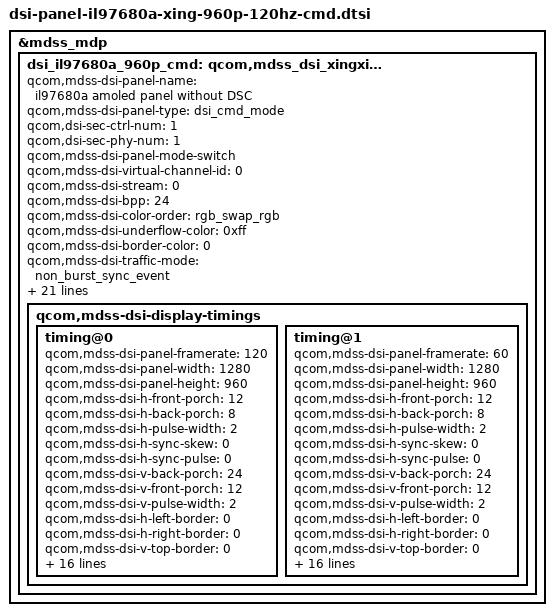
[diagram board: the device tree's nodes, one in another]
&mdss_mdp {
	dsi_il97680a_960p_cmd: qcom,mdss_dsi_xingxing_4_5_1280_960_cmd {
		qcom,mdss-dsi-panel-name =
		  "il97680a amoled panel without DSC";
		qcom,mdss-dsi-panel-type = "dsi_cmd_mode";
		qcom,dsi-sec-ctrl-num = <1>;
		qcom,dsi-sec-phy-num = <1>;


		qcom,mdss-dsi-panel-mode-switch;

		qcom,mdss-dsi-virtual-channel-id = <0>;
		qcom,mdss-dsi-stream = <0>;
		qcom,mdss-dsi-bpp = <24>;
		qcom,mdss-dsi-color-order = "rgb_swap_rgb";
		qcom,mdss-dsi-underflow-color = <0xff>;
		qcom,mdss-dsi-border-color = <0>;

		qcom,mdss-dsi-traffic-mode = "non_burst_sync_event";
		qcom,mdss-dsi-lane-map = "lane_map_0123";
		qcom,mdss-dsi-bllp-eof-power-mode;
		qcom,mdss-dsi-bllp-power-mode;
		qcom,mdss-dsi-lane-0-state;
		qcom,mdss-dsi-lane-1-state;
		qcom,mdss-dsi-lane-2-state;
		qcom,mdss-dsi-lane-3-state;
		qcom,mdss-dsi-dma-trigger = "trigger_sw";
		qcom,mdss-dsi-mdp-trigger = "none";
		qcom,mdss-dsi-reset-sequence = <1 20>, <0 20>, <1 20>;
		qcom,mdss-dsi-te-pin-select = <1>;
		qcom,mdss-dsi-wr-mem-start = <0x2c>;
		qcom,mdss-dsi-wr-mem-continue = <0x3c>;
		qcom,mdss-dsi-te-dcs-command = <1>;
		qcom,mdss-dsi-te-check-enable;
		// qcom,mdss-pan-physical-width-dimension = <68>;
		qcom,mdss-dsi-te-using-te-pin;
	//	qcom,mdss-dsi-te-using-wd;
		qcom,mdss-dsi-panel-hdr-enabled;
		qcom,mdss-dsi-panel-hdr-color-primaries = <14500 15500 32000
			17000 15500 30000 8000 3000>;
		qcom,mdss-dsi-panel-peak-brightness = <4200000>;
		qcom,mdss-dsi-panel-blackness-level = <3230>;

		qcom,mdss-dsi-display-timings {
			timing@0 {
				qcom,mdss-dsi-panel-framerate = <120>;
				qcom,mdss-dsi-panel-width = <1280>;
				qcom,mdss-dsi-panel-height = <960>;
				qcom,mdss-dsi-h-front-porch = <12>;
				qcom,mdss-dsi-h-back-porch = <8>;
				qcom,mdss-dsi-h-pulse-width = <2>;
				qcom,mdss-dsi-h-sync-skew = <0>;
				qcom,mdss-dsi-h-sync-pulse = <0>;
				qcom,mdss-dsi-v-back-porch = <24>;
				qcom,mdss-dsi-v-front-porch = <12>;
				qcom,mdss-dsi-v-pulse-width = <2>;
				qcom,mdss-dsi-h-left-border = <0>;
				qcom,mdss-dsi-h-right-border = <0>;
				qcom,mdss-dsi-v-top-border = <0>;
				qcom,mdss-dsi-v-bottom-border = <0>;
				qcom,mdss-dsi-panel-jitter = <0x3 0x1>;

				qcom,mdss-dsi-timing-switch-command = [
					39 01 00 00 00 00 04 FF 5A A5 00
					39 01 00 00 00 00 02 60 00
				];


				qcom,mdss-dsi-on-command = [
					39 01 00 00 00 00 04 FF 5A A5 08
					39 01 00 00 00 00 02 C8 62
					39 01 00 00 00 00 04 FF 5A A5 21
					39 01 00 00 00 00 02 A4 38
					39 01 00 00 00 00 04 FF 5A A5 23
					39 01 00 00 00 00 02 85 15
					39 01 00 00 00 00 04 FF 5A A5 00
					39 01 00 00 00 00 02 60 00
					39 01 00 00 00 00 02 6D 00
					05 01 00 00 00 00 01 35
					39 01 00 00 00 00 02 53 20
					39 01 00 00 00 00 05 51 0D 75 00 00
					05 01 00 00 78 00 01 11
					
				];
				qcom,mdss-dsi-post-panel-on-command = [
					05 01 00 00 32 00 01 29
					39 01 00 00 00 00 04 FF 5A A5 22
					39 01 00 00 00 00 02 E1 01
					39 01 00 00 00 00 04 FF 5A A5 00
				];
				qcom,mdss-dsi-off-command = [
					05 01 00 00 14 00 02 28 00
					05 01 00 00 78 00 02 10 00];
				qcom,mdss-dsi-on-command-state = "dsi_lp_mode";
				qcom,mdss-dsi-post-panel-on-command-state = "dsi_lp_mode";
				qcom,mdss-dsi-off-command-state = "dsi_lp_mode";
				qcom,mdss-dsi-timing-switch-command-state =
					"dsi_lp_mode";
			};
			timing@1 {
				qcom,mdss-dsi-panel-framerate = <60>;
				qcom,mdss-dsi-panel-width = <1280>;
				qcom,mdss-dsi-panel-height = <960>;
				qcom,mdss-dsi-h-front-porch = <12>;
				qcom,mdss-dsi-h-back-porch = <8>;
				qcom,mdss-dsi-h-pulse-width = <2>;
				qcom,mdss-dsi-h-sync-skew = <0>;
				qcom,mdss-dsi-h-sync-pulse = <0>;
				qcom,mdss-dsi-v-back-porch = <24>;
				qcom,mdss-dsi-v-front-porch = <12>;
				qcom,mdss-dsi-v-pulse-width = <2>;
				qcom,mdss-dsi-h-left-border = <0>;
				qcom,mdss-dsi-h-right-border = <0>;
				qcom,mdss-dsi-v-top-border = <0>;
				qcom,mdss-dsi-v-bottom-border = <0>;
				qcom,mdss-dsi-panel-jitter = <0x3 0x1>;

				qcom,mdss-dsi-timing-switch-command = [
					39 01 00 00 00 00 04 FF 5A A5 00
					39 01 00 00 00 00 02 60 01
				];


				qcom,mdss-dsi-on-command = [
						39 01 00 00 00 00 04 FF 5A A5 08
						39 01 00 00 00 00 02 C8 62
						39 01 00 00 00 00 04 FF 5A A5 21
						39 01 00 00 00 00 02 A4 38
						39 01 00 00 00 00 04 FF 5A A5 23
						39 01 00 00 00 00 02 85 15
						39 01 00 00 00 00 04 FF 5A A5 00
						39 01 00 00 00 00 02 60 01
						39 01 00 00 00 00 02 6D 00
						05 01 00 00 00 00 01 35
						39 01 00 00 00 00 02 53 20
						39 01 00 00 00 00 05 51 0D 75 00 00
						05 01 00 00 78 00 01 11
						
				];
				qcom,mdss-dsi-post-panel-on-command = [
					  05 01 00 00 32 00 01 29
					  39 01 00 00 00 00 04 FF 5A A5 22
					  39 01 00 00 00 00 02 E1 01
					  39 01 00 00 00 00 04 FF 5A A5 00
				];
				qcom,mdss-dsi-off-command = [
					05 01 00 00 14 00 02 28 00
					05 01 00 00 78 00 02 10 00];
				qcom,mdss-dsi-on-command-state = "dsi_lp_mode";
				qcom,mdss-dsi-post-panel-on-command-state = "dsi_lp_mode";
				qcom,mdss-dsi-off-command-state = "dsi_lp_mode";
				qcom,mdss-dsi-timing-switch-command-state =
					"dsi_lp_mode";
			};
			

		};
	};
};
